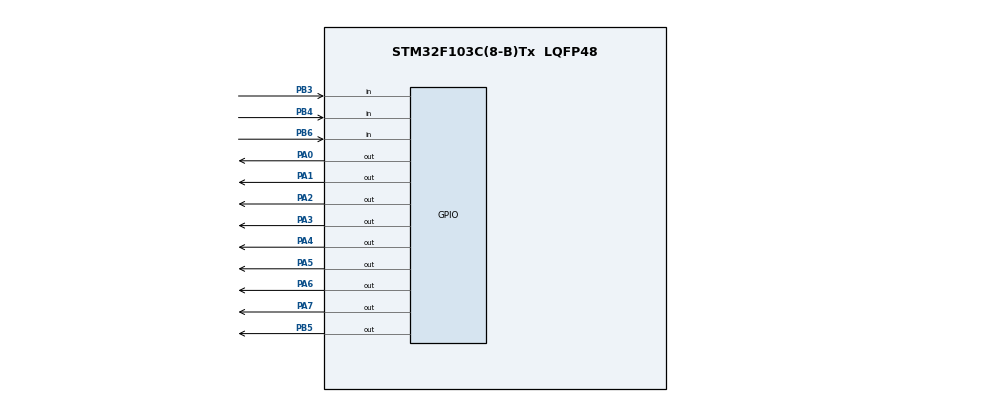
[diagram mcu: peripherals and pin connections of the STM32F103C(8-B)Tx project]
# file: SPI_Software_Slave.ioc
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Mcu.Family=STM32F1
Mcu.Name=STM32F103C(8-B)Tx
Mcu.Package=LQFP48
NVIC.PriorityGroup=NVIC_PRIORITYGROUP_4
PA0-WKUP.Signal=GPIO_Output
PA1.Signal=GPIO_Output
PA13.Mode=Serial_Wire
PA13.Signal=SYS_JTMS-SWDIO
PA14.Mode=Serial_Wire
PA14.Signal=SYS_JTCK-SWCLK
PA2.Signal=GPIO_Output
PA3.Signal=GPIO_Output
PA4.Signal=GPIO_Output
PA5.Signal=GPIO_Output
PA6.Signal=GPIO_Output
PA7.Signal=GPIO_Output
PB3.GPIO_PuPd=GPIO_PULLDOWN
PB3.Signal=GPIO_Input
PB4.GPIO_PuPd=GPIO_PULLDOWN
PB4.Signal=GPIO_Input
PB5.Signal=GPIO_Output
PB6.GPIO_PuPd=GPIO_PULLUP
PB6.Signal=GPIO_Input
ProjectManager.HeapSize=0x200
ProjectManager.StackSize=0x400
ProjectManager.TargetToolchain=MDK-ARM V5
RCC.APB1Freq_Value=8000000
RCC.APB2Freq_Value=8000000
board=custom

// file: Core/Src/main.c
/* USER CODE BEGIN Header */
/**
  ******************************************************************************
  * @file           : main.c
  * @brief          : Main program body
  ******************************************************************************
  * @attention
  *
  * Copyright (c) 2023 STMicroelectronics.
  * All rights reserved.
  *
  * This software is licensed under terms that can be found in the LICENSE file
  * in the root directory of this software component.
  * If no LICENSE file comes with this software, it is provided AS-IS.
  *
  ******************************************************************************
  */
/* USER CODE END Header */
#include "main.h"

#define SCLK GPIO_PIN_3
#define MOSI GPIO_PIN_4
#define MISO GPIO_PIN_5
#define CS GPIO_PIN_6

uint8_t RxBuffer;
uint8_t TxBuffer = 0;
uint8_t count = 0;

void SystemClock_Config(void);
static void MX_GPIO_Init(void);

void SPI_Software_Slave_init(){
	HAL_GPIO_WritePin(GPIOB, MISO, 0);
}

uint8_t SPI_Software_Slave_Receive(){
	uint8_t temp;
	RxBuffer = 0;
	if(HAL_GPIO_ReadPin(GPIOB, CS) == 0){
		for (uint8_t i = 0; i < 8;){
			temp = 0;
			while(HAL_GPIO_ReadPin(GPIOB, SCLK) == 1){
				if(temp == 0){
					RxBuffer = RxBuffer << 1;
					RxBuffer = RxBuffer | HAL_GPIO_ReadPin(GPIOB, MOSI);
					temp = 1;
					i++;
				}
			}
		}
	}
	return RxBuffer;
}

void SPI_Software_Slave_Transmit(uint8_t mData){
	uint8_t temp;

	for(uint8_t i = 0; i < 8;){
		if(HAL_GPIO_ReadPin(GPIOB, CS) == 0){

			temp = 0;
			if((mData&0x80) == 0){
				HAL_GPIO_WritePin(GPIOB, MISO, 0);
			}
			else{
				HAL_GPIO_WritePin(GPIOB, MISO, 1);
			}
			while(HAL_GPIO_ReadPin(GPIOB, SCLK) == 1){
				if(temp == 0){
					mData = mData << 1;
					temp = 1;
					i++;
				}
			}
		}
	}
}

uint8_t SPI_Software_Slave_TransmitReceive(uint8_t mData){
	uint8_t temp;
	RxBuffer = 0;

	for(uint8_t i = 0; i < 8;){
		if(HAL_GPIO_ReadPin(GPIOB, CS) == 0){

			temp = 0;
			if((mData&0x80) == 0){
				HAL_GPIO_WritePin(GPIOB, MISO, 0);
			}
			else{
				HAL_GPIO_WritePin(GPIOB, MISO, 1);
			}
			while(HAL_GPIO_ReadPin(GPIOB, SCLK) == 1){
				if(temp == 0){
					mData = mData << 1;
					RxBuffer = RxBuffer << 1;
					RxBuffer = RxBuffer | HAL_GPIO_ReadPin(GPIOB, MOSI);
					temp = 1;
					i++;
				}
			}
		}
	}
	return RxBuffer;
}

int main(void)
{

  /* MCU Configuration--------------------------------------------------------*/

  /* Reset of all peripherals, Initializes the Flash interface and the Systick. */
  HAL_Init();

  /* Configure the system clock */
  SystemClock_Config();

  /* Initialize all configured peripherals */
  MX_GPIO_Init();

  /* Infinite loop */
  /* USER CODE BEGIN WHILE */

	uint8_t data = 255;

  while (1)
  {
    /* USER CODE END WHILE */
			SPI_Software_Slave_init();
			GPIOA->ODR = SPI_Software_Slave_TransmitReceive(data);
			data--;
  }
}

void SystemClock_Config(void)
{
  RCC_OscInitTypeDef RCC_OscInitStruct = {0};
  RCC_ClkInitTypeDef RCC_ClkInitStruct = {0};

  /** Initializes the RCC Oscillators according to the specified parameters
  * in the RCC_OscInitTypeDef structure.
  */
  RCC_OscInitStruct.OscillatorType = RCC_OSCILLATORTYPE_HSI;
  RCC_OscInitStruct.HSIState = RCC_HSI_ON;
  RCC_OscInitStruct.HSICalibrationValue = RCC_HSICALIBRATION_DEFAULT;
  RCC_OscInitStruct.PLL.PLLState = RCC_PLL_NONE;
  if (HAL_RCC_OscConfig(&RCC_OscInitStruct) != HAL_OK)
  {
    Error_Handler();
  }

  /** Initializes the CPU, AHB and APB buses clocks
  */
  RCC_ClkInitStruct.ClockType = RCC_CLOCKTYPE_HCLK|RCC_CLOCKTYPE_SYSCLK
                              |RCC_CLOCKTYPE_PCLK1|RCC_CLOCKTYPE_PCLK2;
  RCC_ClkInitStruct.SYSCLKSource = RCC_SYSCLKSOURCE_HSI;
  RCC_ClkInitStruct.AHBCLKDivider = RCC_SYSCLK_DIV1;
  RCC_ClkInitStruct.APB1CLKDivider = RCC_HCLK_DIV1;
  RCC_ClkInitStruct.APB2CLKDivider = RCC_HCLK_DIV1;

  if (HAL_RCC_ClockConfig(&RCC_ClkInitStruct, FLASH_LATENCY_0) != HAL_OK)
  {
    Error_Handler();
  }
}

static void MX_GPIO_Init(void)
{
  GPIO_InitTypeDef GPIO_InitStruct = {0};

  /* GPIO Ports Clock Enable */
  __HAL_RCC_GPIOA_CLK_ENABLE();
  __HAL_RCC_GPIOB_CLK_ENABLE();

  /*Configure GPIO pin Output Level */
  HAL_GPIO_WritePin(GPIOA, GPIO_PIN_0|GPIO_PIN_1|GPIO_PIN_2|GPIO_PIN_3
                          |GPIO_PIN_4|GPIO_PIN_5|GPIO_PIN_6|GPIO_PIN_7, GPIO_PIN_RESET);

  /*Configure GPIO pin Output Level */
  HAL_GPIO_WritePin(GPIOB, GPIO_PIN_5, GPIO_PIN_RESET);

  /*Configure GPIO pins : PA0 PA1 PA2 PA3
                           PA4 PA5 PA6 PA7 */
  GPIO_InitStruct.Pin = GPIO_PIN_0|GPIO_PIN_1|GPIO_PIN_2|GPIO_PIN_3
                          |GPIO_PIN_4|GPIO_PIN_5|GPIO_PIN_6|GPIO_PIN_7;
  GPIO_InitStruct.Mode = GPIO_MODE_OUTPUT_PP;
  GPIO_InitStruct.Pull = GPIO_NOPULL;
  GPIO_InitStruct.Speed = GPIO_SPEED_FREQ_LOW;
  HAL_GPIO_Init(GPIOA, &GPIO_InitStruct);

  /*Configure GPIO pins : PB3 PB4 */
  GPIO_InitStruct.Pin = GPIO_PIN_3|GPIO_PIN_4;
  GPIO_InitStruct.Mode = GPIO_MODE_INPUT;
  GPIO_InitStruct.Pull = GPIO_PULLDOWN;
  HAL_GPIO_Init(GPIOB, &GPIO_InitStruct);

  /*Configure GPIO pin : PB5 */
  GPIO_InitStruct.Pin = GPIO_PIN_5;
  GPIO_InitStruct.Mode = GPIO_MODE_OUTPUT_PP;
  GPIO_InitStruct.Pull = GPIO_NOPULL;
  GPIO_InitStruct.Speed = GPIO_SPEED_FREQ_LOW;
  HAL_GPIO_Init(GPIOB, &GPIO_InitStruct);

  /*Configure GPIO pin : PB6 */
  GPIO_InitStruct.Pin = GPIO_PIN_6;
  GPIO_InitStruct.Mode = GPIO_MODE_INPUT;
  GPIO_InitStruct.Pull = GPIO_PULLUP;
  HAL_GPIO_Init(GPIOB, &GPIO_InitStruct);

}

void Error_Handler(void)
{
  __disable_irq();
  while (1)
  {
  }
}
